AUTOSAR XML (schema 4-3-0)
package /Impl_SWC_FDC_ARPkg
  swc implementation Impl_SWC_FDC_type: programming-language=C, sw-version=1.0.0, vendor-id=0, behavior=SWC_FDC_type_IB
    code-descriptors:
      code SRC: artifact-descriptors=autosar-engineering-object={short-label=EngObject, category=SWSRC}
    resource consumption ResourceConsumption
      memory section MEM_SWC_FDC_CAL: size=0, sw-addrmethod=CAL, symbol=CAL
      memory section MEM_SWC_FDC_CODE: size=0, sw-addrmethod=CODE, symbol=CODE
package /SWC_FDC_ARPkg
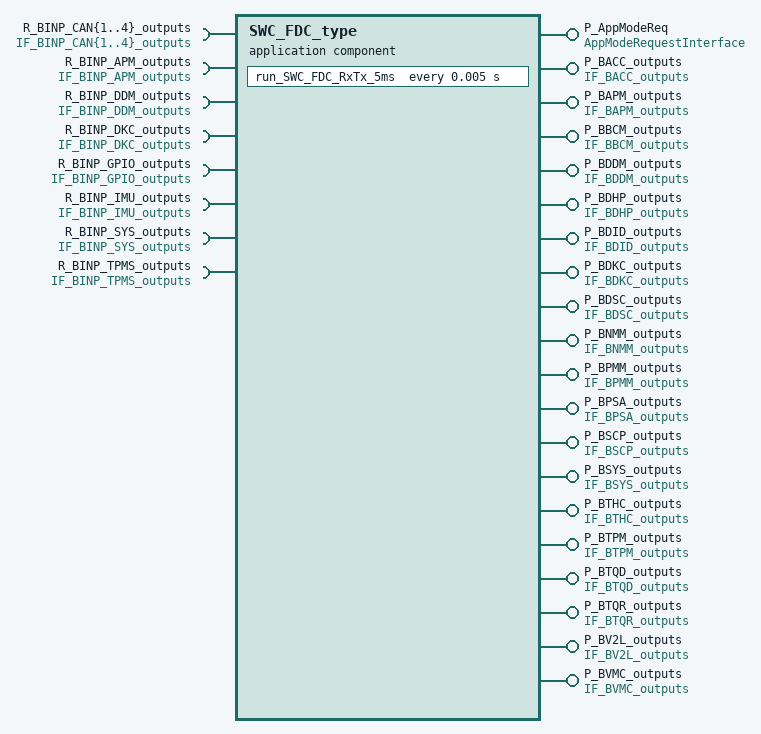
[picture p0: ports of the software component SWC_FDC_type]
  application sw component type SWC_FDC_type
    20 x provide port:
      P_AppModeReq: provided-interface=AppModeRequestInterface
      P_BACC_outputs: provided-interface=IF_BACC_outputs
      P_BAPM_outputs: provided-interface=IF_BAPM_outputs
      P_BBCM_outputs: provided-interface=IF_BBCM_outputs
      P_BDDM_outputs: provided-interface=IF_BDDM_outputs
      P_BDHP_outputs: provided-interface=IF_BDHP_outputs
      P_BDID_outputs: provided-interface=IF_BDID_outputs
      P_BDKC_outputs: provided-interface=IF_BDKC_outputs
      P_BDSC_outputs: provided-interface=IF_BDSC_outputs
      P_BNMM_outputs: provided-interface=IF_BNMM_outputs
      P_BPMM_outputs: provided-interface=IF_BPMM_outputs
      P_BPSA_outputs: provided-interface=IF_BPSA_outputs
      P_BSCP_outputs: provided-interface=IF_BSCP_outputs
      P_BSYS_outputs: provided-interface=IF_BSYS_outputs
      P_BTHC_outputs: provided-interface=IF_BTHC_outputs
      P_BTPM_outputs: provided-interface=IF_BTPM_outputs
      P_BTQD_outputs: provided-interface=IF_BTQD_outputs
      P_BTQR_outputs: provided-interface=IF_BTQR_outputs
      P_BV2L_outputs: provided-interface=IF_BV2L_outputs
      P_BVMC_outputs: provided-interface=IF_BVMC_outputs
    11 x require port:
      R_BINP_CAN{1..4}_outputs: required-interface=IF_BINP_CAN{1..4}_outputs
      R_BINP_APM_outputs: required-interface=IF_BINP_APM_outputs
      R_BINP_DDM_outputs: required-interface=IF_BINP_DDM_outputs
      R_BINP_DKC_outputs: required-interface=IF_BINP_DKC_outputs
      R_BINP_GPIO_outputs: required-interface=IF_BINP_GPIO_outputs
      R_BINP_IMU_outputs: required-interface=IF_BINP_IMU_outputs
      R_BINP_SYS_outputs: required-interface=IF_BINP_SYS_outputs
      R_BINP_TPMS_outputs: required-interface=IF_BINP_TPMS_outputs
    behavior SWC_FDC_type_IB: data-type-mapping=AppModeTypeMap, handle-termination-and-restart=NO-SUPPORT
      timing event TE_5ms: start-on-event=run_SWC_FDC_RxTx_5ms, period=0.005
      runnable run_SWC_FDC_RxTx_5ms
        data-receive-point-by-arguments:
          11 x access:
            drparg_BINP_CAN{1..4}_outputs: accessed-variable=R_BINP_CAN{1..4}_outputs.BINP_CAN{1..4}_outputs
            drparg_BINP_APM_outputs: accessed-variable=R_BINP_APM_outputs.BINP_APM_outputs
            drparg_BINP_DDM_outputs: accessed-variable=R_BINP_DDM_outputs.BINP_DDM_outputs
            drparg_BINP_DKC_outputs: accessed-variable=R_BINP_DKC_outputs.BINP_DKC_outputs
            drparg_BINP_GPIO_outputs: accessed-variable=R_BINP_GPIO_outputs.BINP_GPIO_outputs
            drparg_BINP_IMU_outputs: accessed-variable=R_BINP_IMU_outputs.BINP_IMU_outputs
            drparg_BINP_SYS_outputs: accessed-variable=R_BINP_SYS_outputs.BINP_SYS_outputs
            drparg_BINP_TPMS_outputs: accessed-variable=R_BINP_TPMS_outputs.BINP_TPMS_outputs
        data-send-points:
          19 x access:
            dsp_BACC_outputs: accessed-variable=P_BACC_outputs.BACC_outputs
            dsp_BAPM_outputs: accessed-variable=P_BAPM_outputs.BAPM_outputs
            dsp_BBCM_outputs: accessed-variable=P_BBCM_outputs.BBCM_outputs
            dsp_BDDM_outputs: accessed-variable=P_BDDM_outputs.BDDM_outputs
            dsp_BDHP_outputs: accessed-variable=P_BDHP_outputs.BDHP_outputs
            dsp_BDID_outputs: accessed-variable=P_BDID_outputs.BDID_outputs
            dsp_BDKC_outputs: accessed-variable=P_BDKC_outputs.BDKC_outputs
            dsp_BDSC_outputs: accessed-variable=P_BDSC_outputs.BDSC_outputs
            dsp_BNMM_outputs: accessed-variable=P_BNMM_outputs.BNMM_outputs
            dsp_BPMM_outputs: accessed-variable=P_BPMM_outputs.BPMM_outputs
            dsp_BPSA_outputs: accessed-variable=P_BPSA_outputs.BPSA_outputs
            dsp_BSCP_outputs: accessed-variable=P_BSCP_outputs.BSCP_outputs
            dsp_BSYS_outputs: accessed-variable=P_BSYS_outputs.BSYS_outputs
            dsp_BTHC_outputs: accessed-variable=P_BTHC_outputs.BTHC_outputs
            dsp_BTPM_outputs: accessed-variable=P_BTPM_outputs.BTPM_outputs
            dsp_BTQD_outputs: accessed-variable=P_BTQD_outputs.BTQD_outputs
            dsp_BTQR_outputs: accessed-variable=P_BTQR_outputs.BTQR_outputs
            dsp_BV2L_outputs: accessed-variable=P_BV2L_outputs.BV2L_outputs
            dsp_BVMC_outputs: accessed-variable=P_BVMC_outputs.BVMC_outputs
